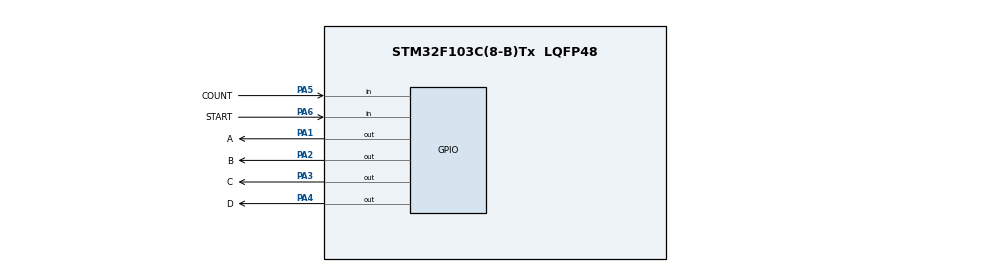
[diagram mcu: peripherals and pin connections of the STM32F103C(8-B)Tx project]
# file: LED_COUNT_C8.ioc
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Mcu.Family=STM32F1
Mcu.Name=STM32F103C(8-B)Tx
Mcu.Package=LQFP48
NVIC.PriorityGroup=NVIC_PRIORITYGROUP_4
PA1.GPIO_Label=A
PA1.Signal=GPIO_Output
PA2.GPIO_Label=B
PA2.Signal=GPIO_Output
PA3.GPIO_Label=C
PA3.Signal=GPIO_Output
PA4.GPIO_Label=D
PA4.Signal=GPIO_Output
PA5.GPIO_Label=COUNT
PA5.GPIO_PuPd=GPIO_PULLDOWN
PA5.Signal=GPIO_Input
PA6.GPIO_Label=START
PA6.Signal=GPIO_Input
ProjectManager.HeapSize=0x200
ProjectManager.StackSize=0x400
ProjectManager.TargetToolchain=STM32CubeIDE
RCC.APB1Freq_Value=8000000
RCC.APB2Freq_Value=8000000
board=custom

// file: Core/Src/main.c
/* USER CODE BEGIN Header */
/**
  ******************************************************************************
  * @file           : main.c
  * @brief          : Main program body
  ******************************************************************************
  * @attention
  *
  * Copyright (c) 2026 STMicroelectronics.
  * All rights reserved.
  *
  * This software is licensed under terms that can be found in the LICENSE file
  * in the root directory of this software component.
  * If no LICENSE file comes with this software, it is provided AS-IS.
  *
  ******************************************************************************
  */
/* USER CODE END Header */
#include "main.h"

void SystemClock_Config(void);
static void MX_GPIO_Init(void);

int a[4]={A_Pin,B_Pin,C_Pin,D_Pin};
int c=0;
void count(void){

		c++;
	}
void display(void){
	for(int i=0;i<=4;i++){
	if(c&(1<< i))
	{
		HAL_GPIO_WritePin(GPIOA,a[i],GPIO_PIN_SET);
		//c=0;
	}
	else{
		HAL_GPIO_WritePin(GPIOA,a[i],GPIO_PIN_RESET);
	}
}}
int main(void)
{

  /* MCU Configuration--------------------------------------------------------*/

  /* Reset of all peripherals, Initializes the Flash interface and the Systick. */
  HAL_Init();

  /* Configure the system clock */
  SystemClock_Config();

  /* Initialize all configured peripherals */
  MX_GPIO_Init();

  /* Infinite loop */
  /* USER CODE BEGIN WHILE */
  while (1)
  {
	  if(HAL_GPIO_ReadPin(GPIOA,COUNT_Pin)==GPIO_PIN_SET){
		  HAL_Delay(50);
	  if(HAL_GPIO_ReadPin(GPIOA,COUNT_Pin)==GPIO_PIN_SET){
		  HAL_GPIO_WritePin(GPIOA,A_Pin|B_Pin|C_Pin|D_Pin,GPIO_PIN_RESET);
		  count();
	  }
	  }
	  else if(HAL_GPIO_ReadPin(GPIOA,START_Pin)==GPIO_PIN_SET){
		  HAL_Delay(50);
		  if(HAL_GPIO_ReadPin(GPIOA,START_Pin)==GPIO_PIN_SET){
			  display();
		  }
	  }
    /* USER CODE END WHILE */

  }
}

void SystemClock_Config(void)
{
  RCC_OscInitTypeDef RCC_OscInitStruct = {0};
  RCC_ClkInitTypeDef RCC_ClkInitStruct = {0};

  /** Initializes the RCC Oscillators according to the specified parameters
  * in the RCC_OscInitTypeDef structure.
  */
  RCC_OscInitStruct.OscillatorType = RCC_OSCILLATORTYPE_HSI;
  RCC_OscInitStruct.HSIState = RCC_HSI_ON;
  RCC_OscInitStruct.HSICalibrationValue = RCC_HSICALIBRATION_DEFAULT;
  RCC_OscInitStruct.PLL.PLLState = RCC_PLL_NONE;
  if (HAL_RCC_OscConfig(&RCC_OscInitStruct) != HAL_OK)
  {
    Error_Handler();
  }

  /** Initializes the CPU, AHB and APB buses clocks
  */
  RCC_ClkInitStruct.ClockType = RCC_CLOCKTYPE_HCLK|RCC_CLOCKTYPE_SYSCLK
                              |RCC_CLOCKTYPE_PCLK1|RCC_CLOCKTYPE_PCLK2;
  RCC_ClkInitStruct.SYSCLKSource = RCC_SYSCLKSOURCE_HSI;
  RCC_ClkInitStruct.AHBCLKDivider = RCC_SYSCLK_DIV1;
  RCC_ClkInitStruct.APB1CLKDivider = RCC_HCLK_DIV1;
  RCC_ClkInitStruct.APB2CLKDivider = RCC_HCLK_DIV1;

  if (HAL_RCC_ClockConfig(&RCC_ClkInitStruct, FLASH_LATENCY_0) != HAL_OK)
  {
    Error_Handler();
  }
}

static void MX_GPIO_Init(void)
{
  GPIO_InitTypeDef GPIO_InitStruct = {0};

  /* GPIO Ports Clock Enable */
  __HAL_RCC_GPIOA_CLK_ENABLE();

  /*Configure GPIO pin Output Level */
  HAL_GPIO_WritePin(GPIOA, A_Pin|B_Pin|C_Pin|D_Pin, GPIO_PIN_RESET);

  /*Configure GPIO pins : A_Pin B_Pin C_Pin D_Pin */
  GPIO_InitStruct.Pin = A_Pin|B_Pin|C_Pin|D_Pin;
  GPIO_InitStruct.Mode = GPIO_MODE_OUTPUT_PP;
  GPIO_InitStruct.Pull = GPIO_NOPULL;
  GPIO_InitStruct.Speed = GPIO_SPEED_FREQ_LOW;
  HAL_GPIO_Init(GPIOA, &GPIO_InitStruct);

  /*Configure GPIO pin : COUNT_Pin */
  GPIO_InitStruct.Pin = COUNT_Pin;
  GPIO_InitStruct.Mode = GPIO_MODE_INPUT;
  GPIO_InitStruct.Pull = GPIO_PULLDOWN;
  HAL_GPIO_Init(COUNT_GPIO_Port, &GPIO_InitStruct);

  /*Configure GPIO pin : START_Pin */
  GPIO_InitStruct.Pin = START_Pin;
  GPIO_InitStruct.Mode = GPIO_MODE_INPUT;
  GPIO_InitStruct.Pull = GPIO_NOPULL;
  HAL_GPIO_Init(START_GPIO_Port, &GPIO_InitStruct);

}

void Error_Handler(void)
{
  __disable_irq();
  while (1)
  {
  }
}
